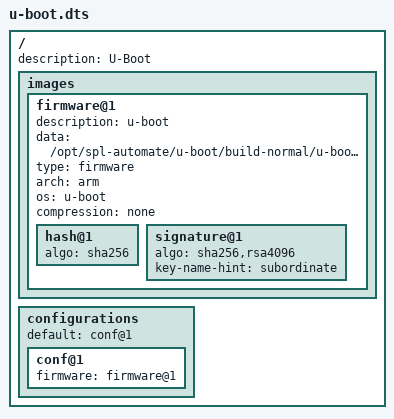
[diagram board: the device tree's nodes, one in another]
/dts-v1/;

/ {
    description = "U-Boot";
    #address-cells = <1>;

    images {
        firmware@1 {
            description = "u-boot";
            data = /incbin/("/opt/spl-automate/u-boot/build-normal/u-boot-nodtb.bin");
            type = "firmware";
            arch = "arm";
            os = "u-boot";
            compression = "none";
            hash@1 {
                algo = "sha256";
            };
            signature@1 {
                algo = "sha256,rsa4096";
                key-name-hint = "subordinate";
            };
        };
    };

    configurations {
        default = "conf@1";
        conf@1 {
            firmware = "firmware@1";
        };
    };
};
